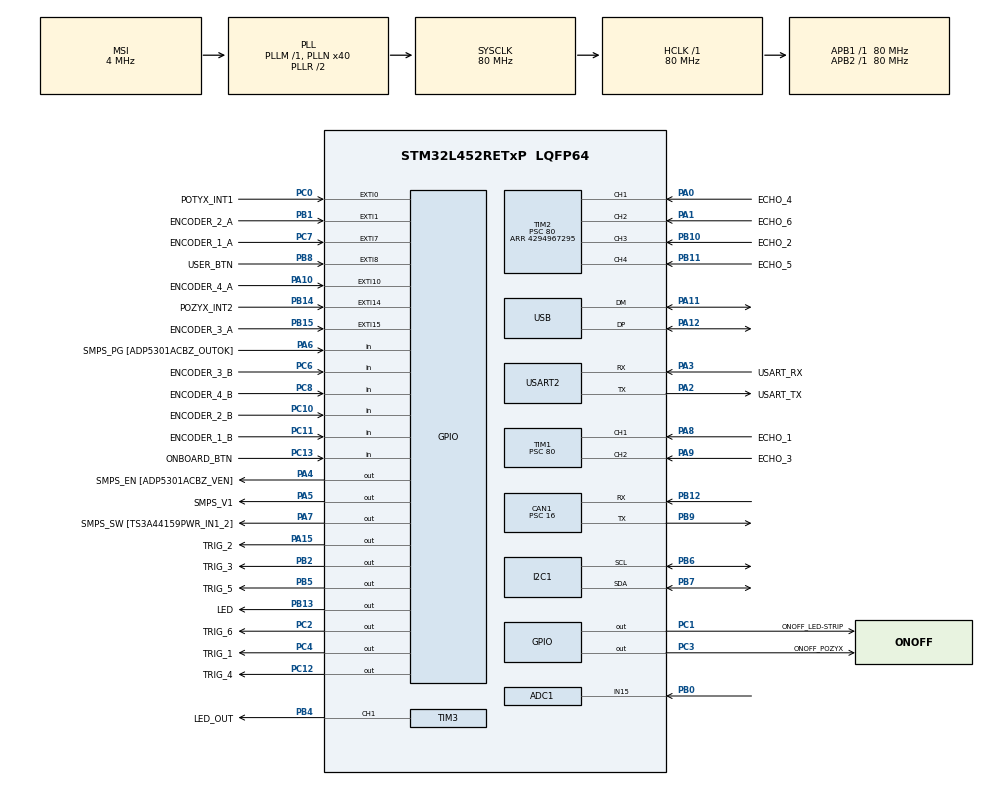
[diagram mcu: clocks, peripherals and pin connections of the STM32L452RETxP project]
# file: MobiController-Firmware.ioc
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ADC1.Channel-1\#ChannelRegularConversion=ADC_CHANNEL_15
ADC1.DataAlign=ADC_DATAALIGN_RIGHT
ADC1.NbrOfConversion=1
ADC1.NbrOfConversionFlag=1
ADC1.OffsetNumber-1\#ChannelRegularConversion=ADC_OFFSET_NONE
ADC1.Rank-1\#ChannelRegularConversion=1
ADC1.SamplingTime-1\#ChannelRegularConversion=ADC_SAMPLETIME_47CYCLES_5
ADC1.master=1
CAN1.BS1=CAN_BS1_5TQ
CAN1.BS2=CAN_BS2_4TQ
CAN1.CalculateBaudRate=500000
CAN1.CalculateTimeBit=2000
CAN1.CalculateTimeQuantum=200.0
CAN1.Prescaler=16
Dma.Request0=TIM3_CH1/TRIG
Dma.TIM3_CH1/TRIG.0.Direction=DMA_MEMORY_TO_PERIPH
Dma.TIM3_CH1/TRIG.0.Instance=DMA1_Channel6
Dma.TIM3_CH1/TRIG.0.MemDataAlignment=DMA_MDATAALIGN_WORD
Dma.TIM3_CH1/TRIG.0.MemInc=DMA_MINC_ENABLE
Dma.TIM3_CH1/TRIG.0.Mode=DMA_CIRCULAR
Dma.TIM3_CH1/TRIG.0.PeriphDataAlignment=DMA_PDATAALIGN_WORD
Dma.TIM3_CH1/TRIG.0.PeriphInc=DMA_PINC_DISABLE
Dma.TIM3_CH1/TRIG.0.Priority=DMA_PRIORITY_VERY_HIGH
I2C1.Timing=0x10909CEC
Mcu.Family=STM32L4
Mcu.Name=STM32L452RETxP
Mcu.Package=LQFP64
NVIC.DMA1_Channel6_IRQn=true\:0\:0\:false\:false\:true\:false\:true\:true
NVIC.EXTI0_IRQn=true\:0\:0\:false\:false\:true\:true\:true\:true
NVIC.EXTI15_10_IRQn=true\:0\:0\:false\:false\:true\:true\:true\:true
NVIC.EXTI1_IRQn=true\:0\:0\:false\:false\:true\:true\:true\:true
NVIC.EXTI9_5_IRQn=true\:0\:0\:false\:false\:true\:true\:true\:true
NVIC.PriorityGroup=NVIC_PRIORITYGROUP_4
NVIC.TIM1_CC_IRQn=true\:0\:0\:false\:false\:true\:true\:true\:true
NVIC.TIM2_IRQn=true\:0\:0\:false\:false\:true\:true\:true\:true
NVIC.TIM6_DAC_IRQn=true\:0\:0\:false\:false\:true\:true\:true\:true
NVIC.USB_IRQn=true\:0\:0\:false\:false\:true\:false\:true\:true
PA0.GPIO_Label=ECHO_4
PA0.Signal=S_TIM2_CH1
PA1.GPIO_Label=ECHO_6
PA1.Signal=S_TIM2_CH2
PA10.GPIO_Label=ENCODER_4_A
PA10.Signal=GPXTI10
PA11.Mode=Device
PA11.Signal=USB_DM
PA12.Mode=Device
PA12.Signal=USB_DP
PA13\ (JTMS/SWDIO).GPIO_Label=TMS
PA13\ (JTMS/SWDIO).Mode=Serial_Wire
PA13\ (JTMS/SWDIO).Signal=SYS_JTMS-SWDIO
PA14\ (JTCK/SWCLK).GPIO_Label=TCK
PA14\ (JTCK/SWCLK).Mode=Serial_Wire
PA14\ (JTCK/SWCLK).Signal=SYS_JTCK-SWCLK
PA15\ (JTDI).GPIO_Label=TRIG_2
PA15\ (JTDI).Signal=GPIO_Output
PA2.GPIO_Label=USART_TX
PA2.GPIO_Mode=GPIO_MODE_AF_PP
PA2.GPIO_PuPd=GPIO_NOPULL
PA2.GPIO_Speed=GPIO_SPEED_FREQ_VERY_HIGH
PA2.Mode=Asynchronous
PA2.Signal=USART2_TX
PA3.GPIO_Label=USART_RX
PA3.GPIO_Mode=GPIO_MODE_AF_PP
PA3.GPIO_PuPd=GPIO_NOPULL
PA3.GPIO_Speed=GPIO_SPEED_FREQ_VERY_HIGH
PA3.Mode=Asynchronous
PA3.Signal=USART2_RX
PA4.GPIO_Label=SMPS_EN [ADP5301ACBZ_VEN]
PA4.Signal=GPIO_Output
PA5.GPIO_Label=SMPS_V1
PA5.GPIO_ModeDefaultOutputPP=GPIO_MODE_OUTPUT_PP
PA5.GPIO_PuPd=GPIO_NOPULL
PA5.GPIO_Speed=GPIO_SPEED_FREQ_LOW
PA5.Signal=GPIO_Output
PA6.GPIO_Label=SMPS_PG [ADP5301ACBZ_OUTOK]
PA6.GPIO_PuPd=GPIO_PULLUP
PA6.Signal=GPIO_Input
PA7.GPIO_Label=SMPS_SW [TS3A44159PWR_IN1_2]
PA7.Signal=GPIO_Output
PA8.GPIO_Label=ECHO_1
PA8.Signal=S_TIM1_CH1
PA9.GPIO_Label=ECHO_3
PA9.Signal=S_TIM1_CH2
PB0.Signal=ADCx_IN15
PB1.GPIO_Label=ENCODER_2_A
PB1.Signal=GPXTI1
PB10.GPIO_Label=ECHO_2
PB10.Signal=S_TIM2_CH3
PB11.GPIO_Label=ECHO_5
PB11.Signal=S_TIM2_CH4
PB12.Mode=CAN_Activate
PB12.Signal=CAN1_RX
PB13.GPIO_Label=LED
PB13.Signal=GPIO_Output
PB14.GPIO_Label=POZYX_INT2
PB14.Signal=GPXTI14
PB15.GPIO_Label=ENCODER_3_A
PB15.Signal=GPXTI15
PB2.GPIO_Label=TRIG_3
PB2.Signal=GPIO_Output
PB3\ (JTDO/TRACESWO).GPIO_Label=SWO
PB3\ (JTDO/TRACESWO).Signal=SYS_JTDO-SWO
PB4\ (NJTRST).GPIO_Label=LED_OUT
PB4\ (NJTRST).GPIO_ModeDefaultPP=GPIO_MODE_AF_PP
PB4\ (NJTRST).GPIO_PuPd=GPIO_NOPULL
PB4\ (NJTRST).GPIO_Speed=GPIO_SPEED_FREQ_VERY_HIGH
PB4\ (NJTRST).Signal=S_TIM3_CH1
PB5.GPIO_Label=TRIG_5
PB5.Signal=GPIO_Output
PB6.GPIO_Pu=GPIO_NOPULL
PB6.Mode=I2C
PB6.Signal=I2C1_SCL
PB7.GPIO_Pu=GPIO_NOPULL
PB7.Mode=I2C
PB7.Signal=I2C1_SDA
PB8.GPIO_Label=USER_BTN
PB8.GPIO_ModeDefaultEXTI=GPIO_MODE_IT_RISING_FALLING
PB8.GPIO_PuPd=GPIO_PULLUP
PB8.Signal=GPXTI8
PB9.Mode=CAN_Activate
PB9.Signal=CAN1_TX
PC0.GPIO_Label=POTYX_INT1
PC0.Signal=GPXTI0
PC1.GPIO_Label=ONOFF_LED-STRIP
PC1.GPIO_ModeDefaultOutputPP=GPIO_MODE_OUTPUT_PP
PC1.GPIO_PuPd=GPIO_NOPULL
PC1.Signal=GPIO_Output
PC10.GPIO_Label=ENCODER_2_B
PC10.Signal=GPIO_Input
PC11.GPIO_Label=ENCODER_1_B
PC11.Signal=GPIO_Input
PC12.GPIO_Label=TRIG_4
PC12.Signal=GPIO_Output
PC13.GPIO_Label=ONBOARD_BTN
PC13.Signal=GPIO_Input
PC14-OSC32_IN\ (PC14).Mode=LSE-External-Oscillator
PC14-OSC32_IN\ (PC14).Signal=RCC_OSC32_IN
PC15-OSC32_OUT\ (PC15).Mode=LSE-External-Oscillator
PC15-OSC32_OUT\ (PC15).Signal=RCC_OSC32_OUT
PC2.GPIO_Label=TRIG_6
PC2.Signal=GPIO_Output
PC3.GPIO_Label=ONOFF_POZYX
PC3.Signal=GPIO_Output
PC4.GPIO_Label=TRIG_1
PC4.Signal=GPIO_Output
PC6.GPIO_Label=ENCODER_3_B
PC6.Signal=GPIO_Input
PC7.GPIO_Label=ENCODER_1_A
PC7.GPIO_ModeDefaultEXTI=GPIO_MODE_IT_RISING
PC7.GPIO_PuPd=GPIO_NOPULL
PC7.Signal=GPXTI7
PC8.GPIO_Label=ENCODER_4_B
PC8.Signal=GPIO_Input
PH0-OSC_IN\ (PH0).GPIO_Label=MCO
PH0-OSC_IN\ (PH0).Mode=HSE-External-Oscillator
PH0-OSC_IN\ (PH0).Signal=RCC_OSC_IN
PH1-OSC_OUT\ (PH1).Mode=HSE-External-Oscillator
PH1-OSC_OUT\ (PH1).Signal=RCC_OSC_OUT
ProjectManager.HeapSize=0x200
ProjectManager.StackSize=0x400
ProjectManager.TargetToolchain=Makefile
RCC.ADCFreq_Value=48000000
RCC.AHBFreq_Value=80000000
RCC.APB1Freq_Value=80000000
RCC.APB1TimFreq_Value=80000000
RCC.APB2Freq_Value=80000000
RCC.APB2TimFreq_Value=80000000
RCC.CortexFreq_Value=80000000
RCC.HCLKFreq_Value=80000000
RCC.HSE_VALUE=8000000
RCC.HSI48_VALUE=48000000
RCC.HSI_VALUE=16000000
RCC.MSI_VALUE=4000000
RCC.PLLN=40
RCC.PLLSAI1N=24
RCC.PREFETCH_ENABLE=1
RCC.SYSCLKFreq_VALUE=80000000
RCC.SYSCLKSource=RCC_SYSCLKSOURCE_PLLCLK
RCC.USBFreq_Value=48000000
RCC.VCOOutputFreq_Value=160000000
SH.ADCx_IN15.0=ADC1_IN15,IN15-Single-Ended
SH.S_TIM1_CH1.0=TIM1_CH1,Input_Capture1_from_TI1
SH.S_TIM1_CH2.0=TIM1_CH2,Input_Capture2_from_TI2
SH.S_TIM2_CH1.0=TIM2_CH1,Input_Capture1_from_TI1
SH.S_TIM2_CH2.0=TIM2_CH2,Input_Capture2_from_TI2
SH.S_TIM2_CH3.0=TIM2_CH3,Input_Capture3_from_TI3
SH.S_TIM2_CH4.0=TIM2_CH4,Input_Capture4_from_TI4
SH.S_TIM3_CH1.0=TIM3_CH1,PWM Generation1 CH1
TIM1.Channel-Input_Capture1_from_TI1=TIM_CHANNEL_1
TIM1.Channel-Input_Capture2_from_TI2=TIM_CHANNEL_2
TIM1.Prescaler=80
TIM2.AutoReloadPreload=TIM_AUTORELOAD_PRELOAD_DISABLE
TIM2.Channel-Input_Capture1_from_TI1=TIM_CHANNEL_1
TIM2.Channel-Input_Capture2_from_TI2=TIM_CHANNEL_2
TIM2.Channel-Input_Capture3_from_TI3=TIM_CHANNEL_3
TIM2.Channel-Input_Capture4_from_TI4=TIM_CHANNEL_4
TIM2.ClockDivision=TIM_CLOCKDIVISION_DIV1
TIM2.Period=4294967295
TIM2.Prescaler=80
TIM3.AutoReloadPreload=TIM_AUTORELOAD_PRELOAD_DISABLE
TIM3.Channel-PWM\ Generation1\ CH1=TIM_CHANNEL_1
TIM6.AutoReloadPreload=TIM_AUTORELOAD_PRELOAD_ENABLE
TIM6.Period=8000
TIM6.Prescaler=100
USART2.VirtualMode-Asynchronous=VM_ASYNC
USB_DEVICE.CLASS_NAME_FS=CDC
USB_DEVICE.MANUFACTURER_STRING=STMicroelectronics
USB_DEVICE.PRODUCT_STRING_CDC_FS=STM32 Virtual ComPort
USB_DEVICE.VirtualMode=Cdc
USB_DEVICE.VirtualModeFS=Cdc_FS
VP_TIM1_VS_ClockSourceINT.Mode=Internal
VP_TIM2_VS_ClockSourceINT.Mode=Internal
VP_TIM3_VS_ClockSourceINT.Mode=Internal
VP_TIM6_VS_ClockSourceINT.Mode=Enable_Timer
VP_USB_DEVICE_VS_USB_DEVICE_CDC_FS.Mode=CDC_FS
board=NUCLEO-L452RE-P

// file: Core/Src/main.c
/* USER CODE BEGIN Header */
/**
 ******************************************************************************
 * @file           : main.c
 * @brief          : Main program body
 ******************************************************************************
 * @attention
 *
 * Copyright (c) 2023 STMicroelectronics.
 * All rights reserved.
 *
 * This software is licensed under terms that can be found in the LICENSE file
 * in the root directory of this software component.
 * If no LICENSE file comes with this software, it is provided AS-IS.
 *
 ******************************************************************************
 */
/* USER CODE END Header */
#include "main.h"
#include "adc.h"
#include "can.h"
#include "dma.h"
#include "i2c.h"
#include "tim.h"
#include "usart.h"
#include "usb_device.h"
#include "gpio.h"

/* USER CODE BEGIN Includes */
#include "cpp_main.hpp"
/* USER CODE END Includes */

void SystemClock_Config(void);
void PeriphCommonClock_Config(void);

int main(void)
{

  /* MCU Configuration--------------------------------------------------------*/

  /* Reset of all peripherals, Initializes the Flash interface and the Systick. */
  HAL_Init();

  /* Configure the system clock */
  SystemClock_Config();

/* Configure the peripherals common clocks */
  PeriphCommonClock_Config();

  /* Initialize all configured peripherals */
  MX_GPIO_Init();
  MX_DMA_Init();
  MX_USART2_UART_Init();
  MX_I2C1_Init();
  MX_TIM2_Init();
  MX_ADC1_Init();
  MX_USB_DEVICE_Init();
  MX_TIM1_Init();
  MX_CAN1_Init();
  MX_TIM3_Init();
  MX_TIM6_Init();
  /* USER CODE BEGIN 2 */
  cpp_main();
  /* USER CODE END 2 */

  /* Infinite loop */
  while (1) {

  }
}

void SystemClock_Config(void)
{
  RCC_OscInitTypeDef RCC_OscInitStruct = {0};
  RCC_ClkInitTypeDef RCC_ClkInitStruct = {0};

  /** Configure the main internal regulator output voltage
  */
  if (HAL_PWREx_ControlVoltageScaling(PWR_REGULATOR_VOLTAGE_SCALE1) != HAL_OK)
  {
    Error_Handler();
  }

  /** Configure LSE Drive Capability
  */
  HAL_PWR_EnableBkUpAccess();
  __HAL_RCC_LSEDRIVE_CONFIG(RCC_LSEDRIVE_LOW);

  /** Initializes the RCC Oscillators according to the specified parameters
  * in the RCC_OscInitTypeDef structure.
  */
  RCC_OscInitStruct.OscillatorType = RCC_OSCILLATORTYPE_LSE|RCC_OSCILLATORTYPE_MSI;
  RCC_OscInitStruct.LSEState = RCC_LSE_ON;
  RCC_OscInitStruct.MSIState = RCC_MSI_ON;
  RCC_OscInitStruct.MSICalibrationValue = 0;
  RCC_OscInitStruct.MSIClockRange = RCC_MSIRANGE_6;
  RCC_OscInitStruct.PLL.PLLState = RCC_PLL_ON;
  RCC_OscInitStruct.PLL.PLLSource = RCC_PLLSOURCE_MSI;
  RCC_OscInitStruct.PLL.PLLM = 1;
  RCC_OscInitStruct.PLL.PLLN = 40;
  RCC_OscInitStruct.PLL.PLLP = RCC_PLLP_DIV7;
  RCC_OscInitStruct.PLL.PLLQ = RCC_PLLQ_DIV2;
  RCC_OscInitStruct.PLL.PLLR = RCC_PLLR_DIV2;
  if (HAL_RCC_OscConfig(&RCC_OscInitStruct) != HAL_OK)
  {
    Error_Handler();
  }

  /** Initializes the CPU, AHB and APB buses clocks
  */
  RCC_ClkInitStruct.ClockType = RCC_CLOCKTYPE_HCLK|RCC_CLOCKTYPE_SYSCLK
                              |RCC_CLOCKTYPE_PCLK1|RCC_CLOCKTYPE_PCLK2;
  RCC_ClkInitStruct.SYSCLKSource = RCC_SYSCLKSOURCE_PLLCLK;
  RCC_ClkInitStruct.AHBCLKDivider = RCC_SYSCLK_DIV1;
  RCC_ClkInitStruct.APB1CLKDivider = RCC_HCLK_DIV1;
  RCC_ClkInitStruct.APB2CLKDivider = RCC_HCLK_DIV1;

  if (HAL_RCC_ClockConfig(&RCC_ClkInitStruct, FLASH_LATENCY_4) != HAL_OK)
  {
    Error_Handler();
  }

  /** Enable MSI Auto calibration
  */
  HAL_RCCEx_EnableMSIPLLMode();
}

void PeriphCommonClock_Config(void)
{
  RCC_PeriphCLKInitTypeDef PeriphClkInit = {0};

  /** Initializes the peripherals clock
  */
  PeriphClkInit.PeriphClockSelection = RCC_PERIPHCLK_USB|RCC_PERIPHCLK_ADC;
  PeriphClkInit.AdcClockSelection = RCC_ADCCLKSOURCE_PLLSAI1;
  PeriphClkInit.UsbClockSelection = RCC_USBCLKSOURCE_PLLSAI1;
  PeriphClkInit.PLLSAI1.PLLSAI1Source = RCC_PLLSOURCE_MSI;
  PeriphClkInit.PLLSAI1.PLLSAI1M = 1;
  PeriphClkInit.PLLSAI1.PLLSAI1N = 24;
  PeriphClkInit.PLLSAI1.PLLSAI1P = RCC_PLLP_DIV7;
  PeriphClkInit.PLLSAI1.PLLSAI1Q = RCC_PLLQ_DIV2;
  PeriphClkInit.PLLSAI1.PLLSAI1R = RCC_PLLR_DIV2;
  PeriphClkInit.PLLSAI1.PLLSAI1ClockOut = RCC_PLLSAI1_48M2CLK|RCC_PLLSAI1_ADC1CLK;
  if (HAL_RCCEx_PeriphCLKConfig(&PeriphClkInit) != HAL_OK)
  {
    Error_Handler();
  }
}

void Error_Handler(void)
{
  __disable_irq();
  while (1) {
  }
}
